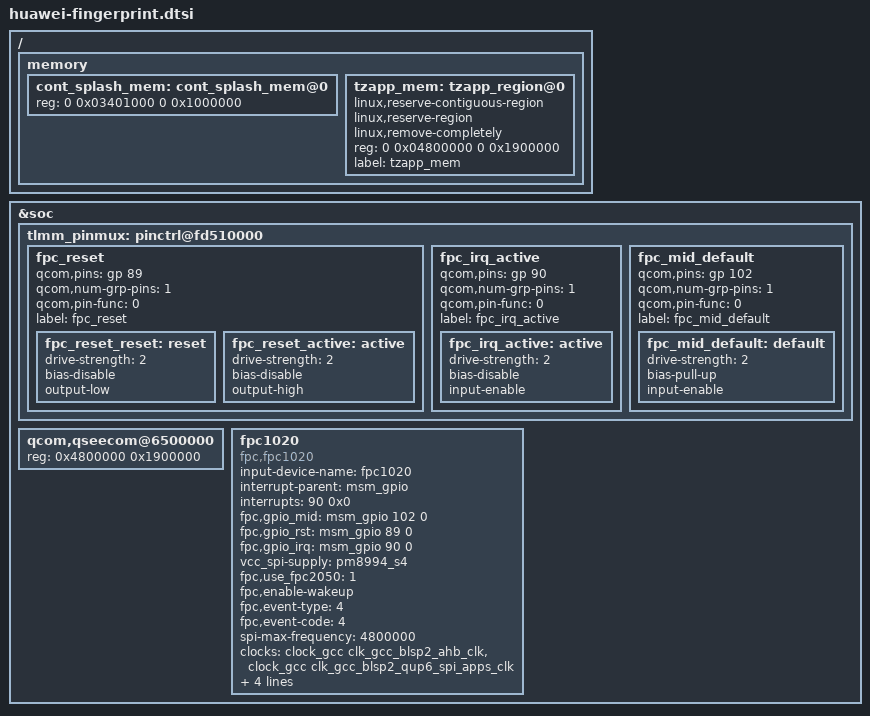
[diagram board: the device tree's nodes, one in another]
/* Copyright (c) 2014-2015, The Linux Foundation. All rights reserved.
 *
 * This program is free software; you can redistribute it and/or modify
 * it under the terms of the GNU General Public License version 2 and
 * only version 2 as published by the Free Software Foundation.
 *
 * This program is distributed in the hope that it will be useful,
 * but WITHOUT ANY WARRANTY; without even the implied warranty of
 * MERCHANTABILITY or FITNESS FOR A PARTICULAR PURPOSE.  See the
 * GNU General Public License for more details.
 */

/ {
	memory {
		cont_splash_mem: cont_splash_mem@0 {
			reg = <0 0x03401000 0 0x1000000>;
		};
		tzapp_mem: tzapp_region@0 {
			linux,reserve-contiguous-region;
			linux,reserve-region;
			linux,remove-completely;
			reg = <0 0x04800000 0 0x1900000>;
			label = "tzapp_mem";
		};
	};
};

&soc {
	tlmm_pinmux: pinctrl@fd510000 {
		fpc_reset {
			qcom,pins = <&gp 89>;
			qcom,num-grp-pins = <1>;
			qcom,pin-func = <0>;
			label = "fpc_reset";
			fpc_reset_reset: reset {
				drive-strength = <2>;
				bias-disable;
				output-low;
			};
			fpc_reset_active: active {
				drive-strength = <2>;
				bias-disable;
				output-high;
			};
		};
		fpc_irq_active {
			qcom,pins = <&gp 90>;
			qcom,num-grp-pins = <1>;
			qcom,pin-func = <0>;
			label = "fpc_irq_active";
			fpc_irq_active: active {
				drive-strength = <2>;
				bias-disable;
				input-enable;
			};
		};
		fpc_mid_default {
			qcom,pins = <&gp 102>;
			qcom,num-grp-pins = <1>;
			qcom,pin-func = <0>;
			label = "fpc_mid_default";
			fpc_mid_default: default {
				drive-strength = <2>;
				bias-pull-up;
				input-enable;
			};
		};
	};
	qcom,qseecom@6500000 {
		reg = <0x4800000 0x1900000>;
	};
	fpc1020 {
		compatible = "fpc,fpc1020";
		input-device-name = "fpc1020";
		interrupt-parent = <&msm_gpio>;
		interrupts = <90 0x0>;
		fpc,gpio_mid = <&msm_gpio 102 0>;
		fpc,gpio_rst    = <&msm_gpio 89 0>;
		fpc,gpio_irq    = <&msm_gpio 90 0>;
		vcc_spi-supply  = <&pm8994_s4>;
		fpc,use_fpc2050 = <1>;
		fpc,enable-wakeup;
		/* EV_MSC, MSC_SCAN */
		fpc,event-type = <4>;
		fpc,event-code = <4>;
		spi-max-frequency = <4800000>;
		clock-names = "iface_clk", "core_clk";
		clocks = <&clock_gcc clk_gcc_blsp2_ahb_clk>,
			<&clock_gcc clk_gcc_blsp2_qup6_spi_apps_clk>;

		pinctrl-names = "fpc1020_reset_reset",
				"fpc1020_reset_active",
				"fpc1020_irq_active",
				"fpc1020_mid_default";
		pinctrl-0 = <&fpc_reset_reset>;
		pinctrl-1 = <&fpc_reset_active>;
		pinctrl-2 = <&fpc_irq_active>;
		pinctrl-3 = <&fpc_mid_default>;
		status = "ok";
	};
};

